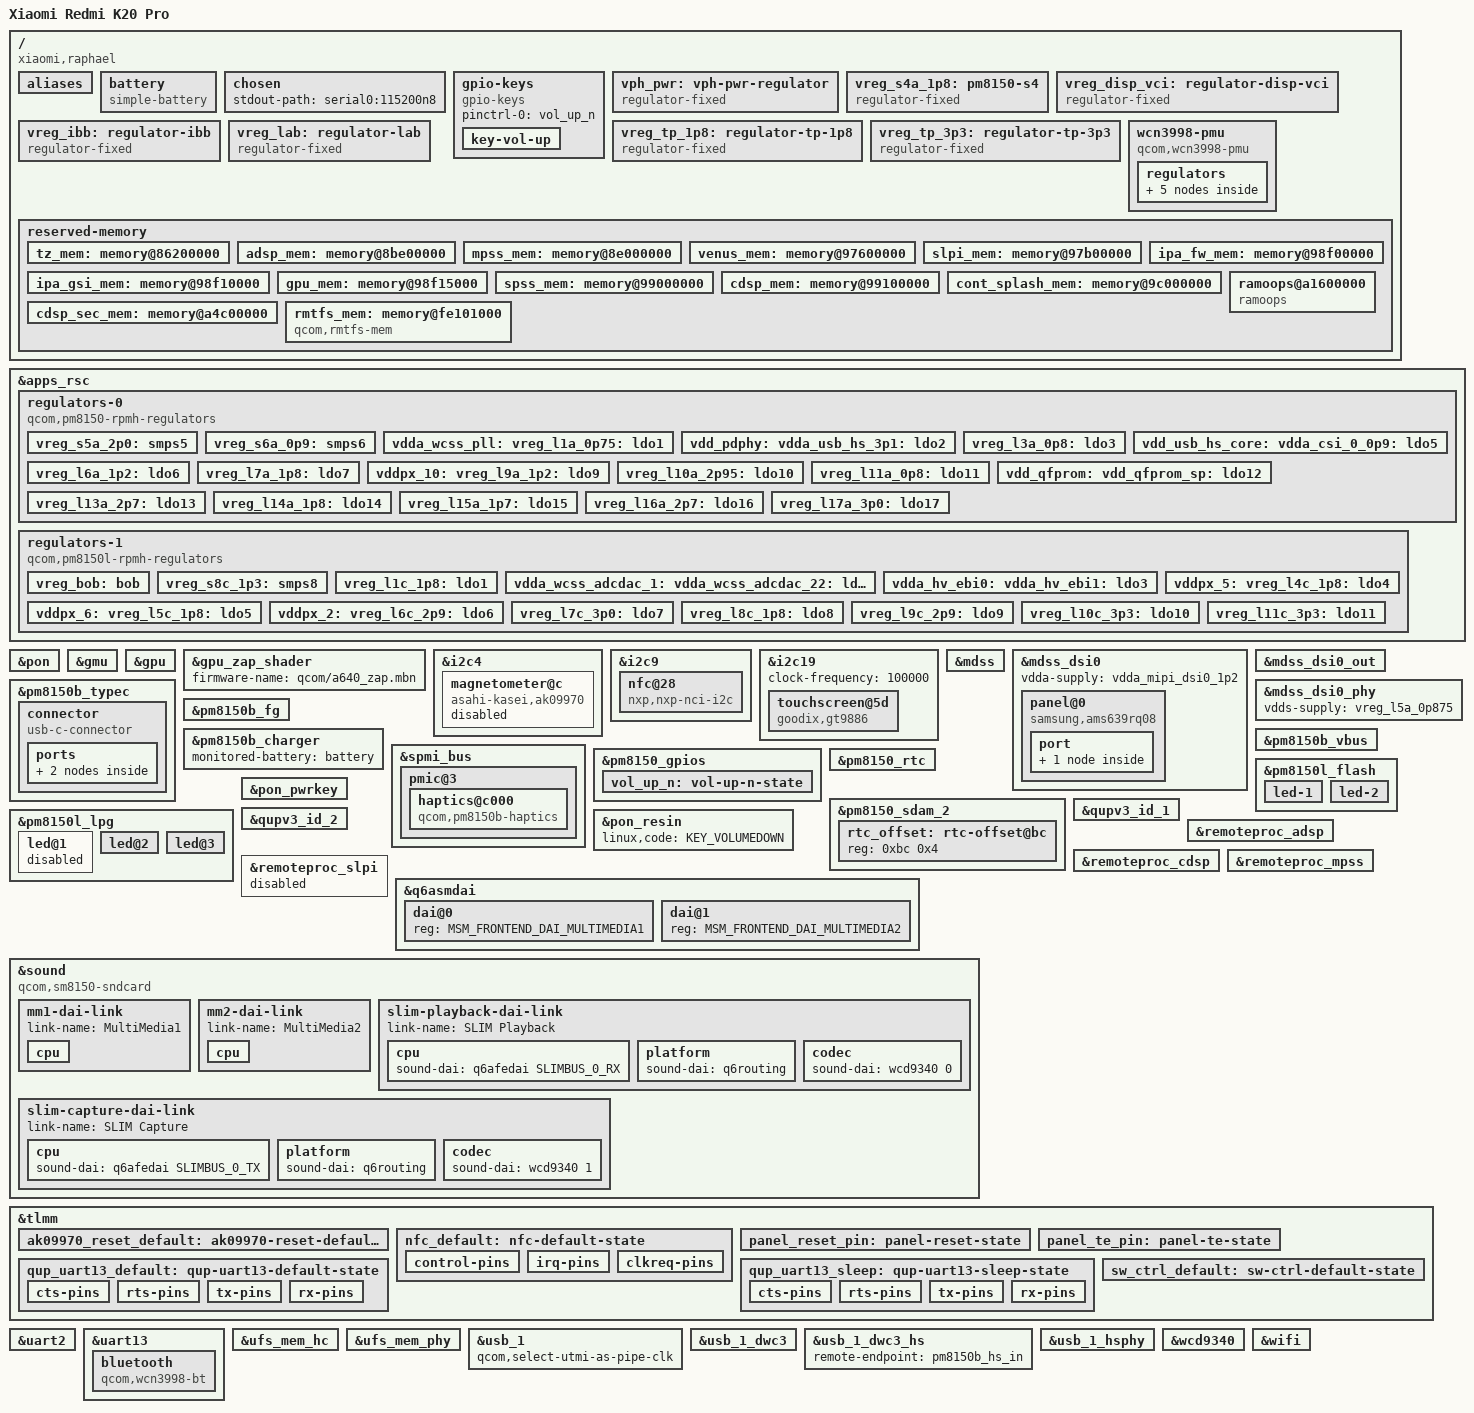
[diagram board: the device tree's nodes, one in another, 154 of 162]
// SPDX-License-Identifier: BSD-3-Clause
/*
 * Copyright (c) 2017-2019, The Linux Foundation. All rights reserved.
 * Copyright (c) 2019, Linaro Limited
 * Copyright (c) 2025, Piyush Raj Chouhan <piyushchouhan1598@gmail.com>
 */

/dts-v1/;

#include <dt-bindings/gpio/gpio.h>
#include <dt-bindings/interrupt-controller/irq.h>
#include <dt-bindings/leds/common.h>
#include <dt-bindings/pinctrl/qcom,pmic-gpio.h>
#include <dt-bindings/regulator/qcom,rpmh-regulator.h>
#include <dt-bindings/sound/qcom,q6afe.h>
#include <dt-bindings/sound/qcom,q6asm.h>
#include <dt-bindings/usb/pd.h>
#include "sm8150.dtsi"
#include "pm8150.dtsi"
#include "pm8150b.dtsi"
#include "pm8150l.dtsi"
#include "sm8150-wcd9340.dtsi"

/* Raphael firmware uses a board-specific reserved-memory layout. */
/delete-node/ &tz_mem;
/delete-node/ &rmtfs_mem;
/delete-node/ &adsp_mem;
/delete-node/ &mpss_mem;
/delete-node/ &venus_mem;
/delete-node/ &slpi_mem;
/delete-node/ &ipa_fw_mem;
/delete-node/ &ipa_gsi_mem;
/delete-node/ &gpu_mem;
/delete-node/ &spss_mem;
/delete-node/ &cdsp_mem;

/ {
	model = "Xiaomi Redmi K20 Pro";
	compatible = "xiaomi,raphael", "qcom,sm8150";
	qcom,msm-id = <339 0x20000>; /* SM8150 v2 */
	qcom,board-id = <40 0>;
	chassis-type = "handset";

	aliases {
		bluetooth0 = &bluetooth;
		serial0 = &uart2;
		serial1 = &uart13;
		wifi0 = &wifi;
	};

	battery: battery {
		compatible = "simple-battery";
		device-chemistry = "lithium-ion-polymer";

		/* Keep rapid-validation charging below the product driver's 1.95 A. */
		constant-charge-current-max-microamp = <1500000>;
		charge-full-design-microamp-hours = <4000000>;
		voltage-min-design-microvolt = <3400000>;
		voltage-max-design-microvolt = <4400000>;
	};

	chosen {
		stdout-path = "serial0:115200n8";
	};

	gpio-keys {
		compatible = "gpio-keys";

		pinctrl-0 = <&vol_up_n>;
		pinctrl-names = "default";

		key-vol-up {
			label = "Volume Up";
			linux,code = <KEY_VOLUMEUP>;
			gpios = <&pm8150_gpios 6 GPIO_ACTIVE_LOW>;
		};
	};

	vph_pwr: vph-pwr-regulator {
		compatible = "regulator-fixed";
		regulator-name = "vph_pwr";
		regulator-min-microvolt = <3700000>;
		regulator-max-microvolt = <3700000>;
	};

	/* PM8150 S4 is always on but is not exposed through RPMh. */
	vreg_s4a_1p8: pm8150-s4 {
		compatible = "regulator-fixed";
		regulator-name = "vreg_s4a_1p8";
		regulator-min-microvolt = <1800000>;
		regulator-max-microvolt = <1800000>;
		regulator-always-on;
		regulator-boot-on;
		vin-supply = <&vph_pwr>;
	};

	vreg_disp_vci: regulator-disp-vci {
		compatible = "regulator-fixed";
		regulator-name = "vreg_disp_vci";
		gpio = <&tlmm 99 GPIO_ACTIVE_HIGH>;
		enable-active-high;
		regulator-boot-on;
	};

	/* These rails are left enabled by the firmware display handoff. */
	vreg_ibb: regulator-ibb {
		compatible = "regulator-fixed";
		regulator-name = "ibb";
		regulator-min-microvolt = <6000000>;
		regulator-max-microvolt = <6000000>;
	};

	vreg_lab: regulator-lab {
		compatible = "regulator-fixed";
		regulator-name = "lab";
		regulator-min-microvolt = <6000000>;
		regulator-max-microvolt = <6000000>;
	};

	vreg_tp_1p8: regulator-tp-1p8 {
		compatible = "regulator-fixed";
		regulator-name = "vreg_tp_1p8";
		regulator-min-microvolt = <1800000>;
		regulator-max-microvolt = <1800000>;
		gpio = <&tlmm 100 GPIO_ACTIVE_HIGH>;
		enable-active-high;
		regulator-boot-on;
		startup-delay-us = <5000>;
	};

	vreg_tp_3p3: regulator-tp-3p3 {
		compatible = "regulator-fixed";
		regulator-name = "vreg_tp_3p3";
		regulator-min-microvolt = <3300000>;
		regulator-max-microvolt = <3300000>;
		gpio = <&tlmm 98 GPIO_ACTIVE_HIGH>;
		enable-active-high;
		regulator-boot-on;
		startup-delay-us = <5000>;
	};

	wcn3998-pmu {
		compatible = "qcom,wcn3998-pmu";

		pinctrl-0 = <&sw_ctrl_default>;
		pinctrl-names = "default";

		vddio-supply = <&vreg_s4a_1p8>;
		vddxo-supply = <&vreg_l7a_1p8>;
		vddrf-supply = <&vreg_l2c_1p3>;
		vddch0-supply = <&vreg_l11c_3p3>;
		vddch1-supply = <&vreg_l10c_3p3>;

		swctrl-gpios = <&tlmm 50 GPIO_ACTIVE_HIGH>;

		regulators {
			vreg_pmu_io: ldo0 {
				regulator-name = "vreg_pmu_io";
			};

			vreg_pmu_xo: ldo1 {
				regulator-name = "vreg_pmu_xo";
			};

			vreg_pmu_rf: ldo2 {
				regulator-name = "vreg_pmu_rf";
			};

			vreg_pmu_ch0: ldo3 {
				regulator-name = "vreg_pmu_ch0";
			};

			vreg_pmu_ch1: ldo4 {
				regulator-name = "vreg_pmu_ch1";
			};
		};
	};

	reserved-memory {
		tz_mem: memory@86200000 {
			reg = <0x0 0x86200000 0x0 0x5500000>;
			no-map;
		};

		adsp_mem: memory@8be00000 {
			reg = <0x0 0x8be00000 0x0 0x2200000>;
			no-map;
		};

		mpss_mem: memory@8e000000 {
			reg = <0x0 0x8e000000 0x0 0x9600000>;
			no-map;
		};

		venus_mem: memory@97600000 {
			reg = <0x0 0x97600000 0x0 0x500000>;
			no-map;
		};

		slpi_mem: memory@97b00000 {
			reg = <0x0 0x97b00000 0x0 0x1400000>;
			no-map;
		};

		ipa_fw_mem: memory@98f00000 {
			reg = <0x0 0x98f00000 0x0 0x10000>;
			no-map;
		};

		ipa_gsi_mem: memory@98f10000 {
			reg = <0x0 0x98f10000 0x0 0x5000>;
			no-map;
		};

		gpu_mem: memory@98f15000 {
			reg = <0x0 0x98f15000 0x0 0x2000>;
			no-map;
		};

		spss_mem: memory@99000000 {
			reg = <0x0 0x99000000 0x0 0x100000>;
			no-map;
		};

		cdsp_mem: memory@99100000 {
			reg = <0x0 0x99100000 0x0 0x1400000>;
			no-map;
		};

		cont_splash_mem: memory@9c000000 {
			reg = <0x0 0x9c000000 0x0 0x2400000>;
			no-map;
		};

		cdsp_sec_mem: memory@a4c00000 {
			reg = <0x0 0xa4c00000 0x0 0x3c00000>;
			no-map;
		};

		ramoops@a1600000 {
			compatible = "ramoops";
			reg = <0x0 0xa1600000 0x0 0x800000>;
			console-size = <0x400000>;
			ecc-size = <0>;
			ftrace-size = <0x20000>;
			pmsg-size = <0x200000>;
			record-size = <0x20000>;
			no-map;
		};

		rmtfs_mem: memory@fe101000 {
			compatible = "qcom,rmtfs-mem";
			reg = <0x0 0xfe101000 0x0 0x300000>;
			no-map;
			qcom,client-id = <1>;
			qcom,vmid = <15>;
		};
	};
};

&apps_rsc {
	regulators-0 {
		compatible = "qcom,pm8150-rpmh-regulators";
		qcom,pmic-id = "a";

		vdd-s1-supply = <&vph_pwr>;
		vdd-s2-supply = <&vph_pwr>;
		vdd-s3-supply = <&vph_pwr>;
		vdd-s4-supply = <&vph_pwr>;
		vdd-s5-supply = <&vph_pwr>;
		vdd-s6-supply = <&vph_pwr>;
		vdd-s7-supply = <&vph_pwr>;
		vdd-s8-supply = <&vph_pwr>;
		vdd-s9-supply = <&vph_pwr>;
		vdd-s10-supply = <&vph_pwr>;

		vdd-l1-l8-l11-supply = <&vreg_s6a_0p9>;
		vdd-l2-l10-supply = <&vreg_bob>;
		vdd-l3-l4-l5-l18-supply = <&vreg_s6a_0p9>;
		vdd-l6-l9-supply = <&vreg_s8c_1p3>;
		vdd-l7-l12-l14-l15-supply = <&vreg_s5a_2p0>;
		vdd-l13-l16-l17-supply = <&vreg_bob>;

		vreg_s5a_2p0: smps5 {
			regulator-min-microvolt = <1904000>;
			regulator-max-microvolt = <2000000>;
		};

		vreg_s6a_0p9: smps6 {
			regulator-min-microvolt = <920000>;
			regulator-max-microvolt = <1128000>;
		};

		vdda_wcss_pll:
		vreg_l1a_0p75: ldo1 {
			regulator-min-microvolt = <752000>;
			regulator-max-microvolt = <752000>;
			regulator-initial-mode = <RPMH_REGULATOR_MODE_HPM>;
		};

		vdd_pdphy:
		vdda_usb_hs_3p1:
		vreg_l2a_3p1: ldo2 {
			regulator-min-microvolt = <3072000>;
			regulator-max-microvolt = <3072000>;
			regulator-initial-mode = <RPMH_REGULATOR_MODE_HPM>;
		};

		vreg_l3a_0p8: ldo3 {
			regulator-min-microvolt = <480000>;
			regulator-max-microvolt = <932000>;
			regulator-initial-mode = <RPMH_REGULATOR_MODE_HPM>;
		};

		vdd_usb_hs_core:
		vdda_csi_0_0p9:
		vdda_csi_1_0p9:
		vdda_csi_2_0p9:
		vdda_csi_3_0p9:
		vdda_dsi_0_0p9:
		vdda_dsi_1_0p9:
		vdda_dsi_0_pll_0p9:
		vdda_dsi_1_pll_0p9:
		vdda_pcie_1ln_core:
		vdda_pcie_2ln_core:
		vdda_pll_hv_cc_ebi01:
		vdda_pll_hv_cc_ebi23:
		vdda_qrefs_0p875_5:
		vdda_sp_sensor:
		vdda_ufs_2ln_core_1:
		vdda_ufs_2ln_core_2:
		vdda_usb_ss_dp_core_1:
		vdda_usb_ss_dp_core_2:
		vdda_qlink_lv:
		vdda_qlink_lv_ck:
		vreg_l5a_0p875: ldo5 {
			regulator-min-microvolt = <880000>;
			regulator-max-microvolt = <880000>;
			regulator-initial-mode = <RPMH_REGULATOR_MODE_HPM>;
		};

		vreg_l6a_1p2: ldo6 {
			regulator-min-microvolt = <1200000>;
			regulator-max-microvolt = <1200000>;
			regulator-initial-mode = <RPMH_REGULATOR_MODE_HPM>;
		};

		vreg_l7a_1p8: ldo7 {
			regulator-min-microvolt = <1800000>;
			regulator-max-microvolt = <1800000>;
			regulator-initial-mode = <RPMH_REGULATOR_MODE_HPM>;
		};

		vddpx_10:
		vreg_l9a_1p2: ldo9 {
			regulator-min-microvolt = <1200000>;
			regulator-max-microvolt = <1200000>;
			regulator-initial-mode = <RPMH_REGULATOR_MODE_HPM>;
		};

		vreg_l10a_2p95: ldo10 {
			regulator-min-microvolt = <2950000>;
			regulator-max-microvolt = <2960000>;
			regulator-initial-mode = <RPMH_REGULATOR_MODE_HPM>;
		};

		vreg_l11a_0p8: ldo11 {
			regulator-min-microvolt = <800000>;
			regulator-max-microvolt = <800000>;
			regulator-initial-mode = <RPMH_REGULATOR_MODE_HPM>;
		};

		vdd_qfprom:
		vdd_qfprom_sp:
		vdda_apc_cs_1p8:
		vdda_gfx_cs_1p8:
		vdda_usb_hs_1p8:
		vdda_qrefs_vref_1p8:
		vddpx_10_a:
		vreg_l12a_1p8: ldo12 {
			regulator-min-microvolt = <1800000>;
			regulator-max-microvolt = <1800000>;
			regulator-initial-mode = <RPMH_REGULATOR_MODE_HPM>;
		};

		vreg_l13a_2p7: ldo13 {
			regulator-min-microvolt = <2704000>;
			regulator-max-microvolt = <2704000>;
			regulator-initial-mode = <RPMH_REGULATOR_MODE_HPM>;
		};

		vreg_l14a_1p8: ldo14 {
			regulator-min-microvolt = <1800000>;
			regulator-max-microvolt = <1880000>;
			regulator-initial-mode = <RPMH_REGULATOR_MODE_HPM>;
		};

		vreg_l15a_1p7: ldo15 {
			regulator-min-microvolt = <1704000>;
			regulator-max-microvolt = <1704000>;
			regulator-initial-mode = <RPMH_REGULATOR_MODE_HPM>;
		};

		vreg_l16a_2p7: ldo16 {
			regulator-min-microvolt = <2704000>;
			regulator-max-microvolt = <2960000>;
			regulator-initial-mode = <RPMH_REGULATOR_MODE_HPM>;
		};

		vreg_l17a_3p0: ldo17 {
			regulator-min-microvolt = <2856000>;
			regulator-max-microvolt = <3008000>;
			regulator-initial-mode = <RPMH_REGULATOR_MODE_HPM>;
		};
	};

	regulators-1 {
		compatible = "qcom,pm8150l-rpmh-regulators";
		qcom,pmic-id = "c";

		vdd-s1-supply = <&vph_pwr>;
		vdd-s2-supply = <&vph_pwr>;
		vdd-s3-supply = <&vph_pwr>;
		vdd-s4-supply = <&vph_pwr>;
		vdd-s5-supply = <&vph_pwr>;
		vdd-s6-supply = <&vph_pwr>;
		vdd-s7-supply = <&vph_pwr>;
		vdd-s8-supply = <&vph_pwr>;

		vdd-l1-l8-supply = <&vreg_s4a_1p8>;
		vdd-l2-l3-supply = <&vreg_s8c_1p3>;
		vdd-l4-l5-l6-supply = <&vreg_bob>;
		vdd-l7-l11-supply = <&vreg_bob>;
		vdd-l9-l10-supply = <&vreg_bob>;
		vdd-bob-supply = <&vph_pwr>;
		vdd-flash-supply = <&vreg_bob>;
		vdd-rgb-supply = <&vreg_bob>;

		vreg_bob: bob {
			regulator-min-microvolt = <3008000>;
			regulator-max-microvolt = <4000000>;
			regulator-initial-mode = <RPMH_REGULATOR_MODE_AUTO>;
			regulator-allow-bypass;
		};

		vreg_s8c_1p3: smps8 {
			regulator-min-microvolt = <1352000>;
			regulator-max-microvolt = <1352000>;
		};

		vreg_l1c_1p8: ldo1 {
			regulator-min-microvolt = <1800000>;
			regulator-max-microvolt = <1800000>;
			regulator-initial-mode = <RPMH_REGULATOR_MODE_HPM>;
		};

		vdda_wcss_adcdac_1:
		vdda_wcss_adcdac_22:
		vreg_l2c_1p3: ldo2 {
			regulator-min-microvolt = <1304000>;
			regulator-max-microvolt = <1304000>;
			regulator-initial-mode = <RPMH_REGULATOR_MODE_HPM>;
		};

		vdda_hv_ebi0:
		vdda_hv_ebi1:
		vdda_hv_ebi2:
		vdda_hv_ebi3:
		vdda_hv_refgen0:
		vdda_mipi_dsi0_1p2:
		vdda_qlink_hv_ck:
		vreg_l3c_1p2: ldo3 {
			regulator-min-microvolt = <1200000>;
			regulator-max-microvolt = <1200000>;
			regulator-initial-mode = <RPMH_REGULATOR_MODE_HPM>;
		};

		vddpx_5:
		vreg_l4c_1p8: ldo4 {
			regulator-min-microvolt = <1704000>;
			regulator-max-microvolt = <2928000>;
			regulator-initial-mode = <RPMH_REGULATOR_MODE_HPM>;
		};

		vddpx_6:
		vreg_l5c_1p8: ldo5 {
			regulator-min-microvolt = <1704000>;
			regulator-max-microvolt = <2928000>;
			regulator-initial-mode = <RPMH_REGULATOR_MODE_HPM>;
		};

		vddpx_2:
		vreg_l6c_2p9: ldo6 {
			regulator-min-microvolt = <1800000>;
			regulator-max-microvolt = <2960000>;
			regulator-initial-mode = <RPMH_REGULATOR_MODE_HPM>;
		};

		vreg_l7c_3p0: ldo7 {
			regulator-min-microvolt = <2856000>;
			regulator-max-microvolt = <3104000>;
			regulator-initial-mode = <RPMH_REGULATOR_MODE_HPM>;
		};

		vreg_l8c_1p8: ldo8 {
			regulator-min-microvolt = <1800000>;
			regulator-max-microvolt = <1800000>;
			regulator-initial-mode = <RPMH_REGULATOR_MODE_HPM>;
		};

		vreg_l9c_2p9: ldo9 {
			regulator-min-microvolt = <2704000>;
			regulator-max-microvolt = <2960000>;
			regulator-initial-mode = <RPMH_REGULATOR_MODE_HPM>;
		};

		vreg_l10c_3p3: ldo10 {
			regulator-min-microvolt = <3000000>;
			regulator-max-microvolt = <3312000>;
			regulator-initial-mode = <RPMH_REGULATOR_MODE_HPM>;
		};

		vreg_l11c_3p3: ldo11 {
			regulator-min-microvolt = <3000000>;
			regulator-max-microvolt = <3312000>;
			regulator-initial-mode = <RPMH_REGULATOR_MODE_HPM>;
		};
	};
};

&pon {
	mode-bootloader = <0x2>;
	mode-recovery = <0x1>;
};

&gmu {
	status = "okay";
};

&gpu {
	status = "okay";
};

&gpu_zap_shader {
	firmware-name = "qcom/a640_zap.mbn";
};

/*
 * The stock DTBO puts the AK09970 on QUPv3 SE4 at address 0x0c.  Keep both
 * the controller and sensor disabled until an attended ID/read-only test;
 * this records the wiring without probing or powering the mechanism.
 */
&i2c4 {
	magnetometer@c {
		compatible = "asahi-kasei,ak09970";
		reg = <0x0c>;

		vdd-supply = <&vreg_l8c_1p8>;
		reset-gpios = <&tlmm 11 GPIO_ACTIVE_LOW>;

		pinctrl-0 = <&ak09970_reset_default>;
		pinctrl-names = "default";
		status = "disabled";
	};
};

/*
 * The stock Raphael DTBO selects QUP9 for its NQ-series NFC controller.
 * Keep the generic NXP NCI compatible until the controller identifies itself
 * on hardware; the stock image carries support for several NQ3xx variants.
 */
&i2c9 {
	status = "okay";

	nfc@28 {
		compatible = "nxp,nxp-nci-i2c";
		reg = <0x28>;

		interrupt-parent = <&tlmm>;
		interrupts = <47 IRQ_TYPE_EDGE_RISING>;

		enable-gpios = <&tlmm 103 GPIO_ACTIVE_HIGH>;
		firmware-gpios = <&tlmm 48 GPIO_ACTIVE_HIGH>;

		pinctrl-0 = <&nfc_default>;
		pinctrl-names = "default";
	};
};

&i2c19 {
	clock-frequency = <100000>;
	status = "okay";

	touchscreen@5d {
		compatible = "goodix,gt9886";
		reg = <0x5d>;

		avdd-supply = <&vreg_tp_3p3>;
		vddio-supply = <&vreg_tp_1p8>;
		interrupts-extended = <&tlmm 122 IRQ_TYPE_LEVEL_LOW>;
		reset-gpios = <&tlmm 54 GPIO_ACTIVE_LOW>;
		touchscreen-size-x = <1080>;
		touchscreen-size-y = <2340>;
	};
};

&mdss {
	status = "okay";
};

&mdss_dsi0 {
	vdda-supply = <&vdda_mipi_dsi0_1p2>;
	status = "okay";

	panel@0 {
		compatible = "samsung,ams639rq08";
		reg = <0>;

		vddio-supply = <&vreg_l14a_1p8>;
		vdd3p3-supply = <&vreg_disp_vci>;
		vsn-supply = <&vreg_ibb>;
		vsp-supply = <&vreg_lab>;

		reset-gpios = <&tlmm 6 GPIO_ACTIVE_LOW>;
		pinctrl-0 = <&panel_reset_pin>, <&panel_te_pin>;
		pinctrl-names = "default";

		port {
			panel_in: endpoint {
				remote-endpoint = <&mdss_dsi0_out>;
			};
		};
	};
};

&mdss_dsi0_out {
	data-lanes = <0 1 2 3>;
	remote-endpoint = <&panel_in>;
};

&mdss_dsi0_phy {
	vdds-supply = <&vreg_l5a_0p875>;
	status = "okay";
};

&pm8150b_typec {
	vdd-vbus-supply = <&pm8150b_vbus>;
	vdd-pdphy-supply = <&vdda_usb_hs_3p1>;
	status = "okay";

	connector {
		compatible = "usb-c-connector";
		power-role = "dual";
		data-role = "dual";
		self-powered;

		source-pdos = <PDO_FIXED(5000, 3000, PDO_FIXED_DUAL_ROLE |
			       PDO_FIXED_USB_COMM | PDO_FIXED_DATA_SWAP)>;
		sink-pdos = <PDO_FIXED(5000, 3000, PDO_FIXED_DUAL_ROLE |
			     PDO_FIXED_USB_COMM | PDO_FIXED_DATA_SWAP)>;
		op-sink-microwatt = <10000000>;

		ports {
			#address-cells = <1>;
			#size-cells = <0>;

			port@0 {
				reg = <0>;

				pm8150b_hs_in: endpoint {
					remote-endpoint = <&usb_1_dwc3_hs>;
				};
			};
		};
	};
};

&pm8150b_fg {
	monitored-battery = <&battery>;
	power-supplies = <&pm8150b_charger>;
	status = "okay";
};

&pm8150b_charger {
	monitored-battery = <&battery>;
	status = "okay";
};

&pm8150b_vbus {
	regulator-min-microamp = <500000>;
	regulator-max-microamp = <1500000>;
	status = "okay";
};

&spmi_bus {
	pmic@3 {
		haptics@c000 {
			compatible = "qcom,pm8150b-haptics";
			reg = <0xc000>;
			interrupts = <0x3 0xc0 0 IRQ_TYPE_EDGE_BOTH>,
				     <0x3 0xc0 1 IRQ_TYPE_EDGE_BOTH>;
			interrupt-names = "hap-sc-irq", "hap-play-irq";

			/* Stock Raphael uses a 3 V ERM at a 6667 us sample rate. */
			qcom,actuator-type = "erm";
			qcom,vmax-mv = <3000>;
			qcom,play-rate-us = <6667>;
		};
	};
};

&pm8150_gpios {
	vol_up_n: vol-up-n-state {
		pins = "gpio6";
		function = PMIC_GPIO_FUNC_NORMAL;
		input-enable;
		bias-pull-up;
	};
};

&pm8150_rtc {
	nvmem-cells = <&rtc_offset>;
	nvmem-cell-names = "offset";
	status = "okay";
};

&pm8150_sdam_2 {
	status = "okay";

	rtc_offset: rtc-offset@bc {
		reg = <0xbc 0x4>;
	};
};

&pm8150l_flash {
	status = "okay";

	led-1 {
		function = LED_FUNCTION_FLASH;
		color = <LED_COLOR_ID_WHITE>;
		led-sources = <1>;
		led-max-microamp = <150000>;
		flash-max-microamp = <1000000>;
		flash-max-timeout-us = <1280000>;
	};

	led-2 {
		function = LED_FUNCTION_FLASH;
		color = <LED_COLOR_ID_YELLOW>;
		led-sources = <2>;
		led-max-microamp = <150000>;
		flash-max-microamp = <1000000>;
		flash-max-timeout-us = <1280000>;
	};
};

&pm8150l_lpg {
	status = "okay";

	led@1 {
		reg = <1>;
		color = <LED_COLOR_ID_WHITE>;
		function = LED_FUNCTION_STATUS;
		status = "disabled";
	};

	led@2 {
		reg = <2>;
		color = <LED_COLOR_ID_RED>;
		function = LED_FUNCTION_STATUS;
		function-enumerator = <0>;
	};

	led@3 {
		reg = <3>;
		color = <LED_COLOR_ID_RED>;
		function = LED_FUNCTION_STATUS;
		function-enumerator = <1>;
	};
};

&pon_pwrkey {
	status = "okay";
};

&pon_resin {
	linux,code = <KEY_VOLUMEDOWN>;
	status = "okay";
};

&qupv3_id_1 {
	status = "okay";
};

&qupv3_id_2 {
	status = "okay";
};

&remoteproc_adsp {
	firmware-name = "qcom/sm8150/Xiaomi/raphael/adsp.mdt";
	status = "okay";
};

&remoteproc_cdsp {
	firmware-name = "qcom/sm8150/Xiaomi/raphael/cdsp.mdt";
	status = "okay";
};

&remoteproc_mpss {
	firmware-name = "qcom/sm8150/Xiaomi/raphael/modem.mdt";
	status = "okay";
};

/* SLPI repeatedly crashes with the available firmware; keep it quarantined. */
&remoteproc_slpi {
	status = "disabled";
};

&q6asmdai {
	dai@0 {
		reg = <MSM_FRONTEND_DAI_MULTIMEDIA1>;
	};

	dai@1 {
		reg = <MSM_FRONTEND_DAI_MULTIMEDIA2>;
	};
};

&sound {
	compatible = "qcom,sm8150-sndcard", "qcom,sdm845-sndcard";
	model = "Xiaomi-Raphael-WCD9340";

	audio-routing =
		"RX_BIAS", "MCLK",
		"AMIC1", "MIC BIAS3",
		"AMIC2", "MIC BIAS2",
		"AMIC3", "MIC BIAS4";

	mm1-dai-link {
		link-name = "MultiMedia1";

		cpu {
			sound-dai = <&q6asmdai MSM_FRONTEND_DAI_MULTIMEDIA1>;
		};
	};

	mm2-dai-link {
		link-name = "MultiMedia2";

		cpu {
			sound-dai = <&q6asmdai MSM_FRONTEND_DAI_MULTIMEDIA2>;
		};
	};

	slim-playback-dai-link {
		link-name = "SLIM Playback";

		cpu {
			sound-dai = <&q6afedai SLIMBUS_0_RX>;
		};

		platform {
			sound-dai = <&q6routing>;
		};

		codec {
			sound-dai = <&wcd9340 0>;
		};
	};

	slim-capture-dai-link {
		link-name = "SLIM Capture";

		cpu {
			sound-dai = <&q6afedai SLIMBUS_0_TX>;
		};

		platform {
			sound-dai = <&q6routing>;
		};

		codec {
			sound-dai = <&wcd9340 1>;
		};
	};
};

&tlmm {
	ak09970_reset_default: ak09970-reset-default-state {
		pins = "gpio11";
		function = "gpio";
		drive-strength = <2>;
		bias-disable;
		output-low;
	};

	nfc_default: nfc-default-state {
		control-pins {
			pins = "gpio48", "gpio103";
			function = "gpio";
			drive-strength = <2>;
			bias-disable;
		};

		irq-pins {
			pins = "gpio47";
			function = "gpio";
			drive-strength = <2>;
			bias-pull-up;
		};

		/* CLKREQ is observed by the downstream driver but not consumed. */
		clkreq-pins {
			pins = "gpio113";
			function = "gpio";
			drive-strength = <2>;
			bias-pull-up;
		};
	};

	panel_reset_pin: panel-reset-state {
		pins = "gpio6";
		function = "gpio";
		drive-strength = <2>;
		bias-disable;
		output-low;
	};

	panel_te_pin: panel-te-state {
		pins = "gpio8";
		function = "mdp_vsync";
		drive-strength = <2>;
		bias-pull-down;
	};

	qup_uart13_default: qup-uart13-default-state {
		cts-pins {
			pins = "gpio43";
			function = "qup13";
			drive-strength = <2>;
			bias-bus-hold;
		};

		rts-pins {
			pins = "gpio44";
			function = "qup13";
			drive-strength = <2>;
			bias-disable;
		};

		tx-pins {
			pins = "gpio45";
			function = "qup13";
			drive-strength = <2>;
			bias-disable;
		};

		rx-pins {
			pins = "gpio46";
			function = "qup13";
			drive-strength = <2>;
			bias-pull-up;
		};
	};

	qup_uart13_sleep: qup-uart13-sleep-state {
		cts-pins {
			pins = "gpio43";
			function = "gpio";
			drive-strength = <2>;
			bias-bus-hold;
		};

		rts-pins {
			pins = "gpio44";
			function = "gpio";
			drive-strength = <2>;
			bias-pull-down;
		};

		tx-pins {
			pins = "gpio45";
			function = "gpio";
			drive-strength = <2>;
			bias-pull-up;
		};

		rx-pins {
			pins = "gpio46";
			function = "gpio";
			drive-strength = <2>;
			bias-pull-up;
		};
	};

	sw_ctrl_default: sw-ctrl-default-state {
		pins = "gpio50";
		function = "gpio";
		bias-pull-down;
	};
};

&uart2 {
	status = "okay";
};

&uart13 {
	/delete-property/ interrupts;
	interrupts-extended = <&intc GIC_SPI 585 IRQ_TYPE_LEVEL_HIGH>,
			      <&tlmm 46 IRQ_TYPE_EDGE_FALLING>;
	pinctrl-0 = <&qup_uart13_default>;
	pinctrl-1 = <&qup_uart13_sleep>;
	pinctrl-names = "default", "sleep";
	status = "okay";

	bluetooth: bluetooth {
		compatible = "qcom,wcn3998-bt";

		vddio-supply = <&vreg_pmu_io>;
		vddxo-supply = <&vreg_pmu_xo>;
		vddrf-supply = <&vreg_pmu_rf>;
		vddch0-supply = <&vreg_pmu_ch0>;
	};
};

&ufs_mem_hc {
	reset-gpios = <&tlmm 175 GPIO_ACTIVE_LOW>;

	vcc-supply = <&vreg_l10a_2p95>;
	vcc-max-microamp = <750000>;
	vccq-supply = <&vreg_l9a_1p2>;
	vccq-max-microamp = <700000>;
	vccq2-supply = <&vreg_s4a_1p8>;
	vccq2-max-microamp = <750000>;

	status = "okay";
};

&ufs_mem_phy {
	vdda-phy-supply = <&vdda_ufs_2ln_core_1>;
	vdda-pll-supply = <&vreg_l3c_1p2>;

	status = "okay";
};

&usb_1 {
	qcom,select-utmi-as-pipe-clk;
	status = "okay";
};

&usb_1_dwc3 {
	dr_mode = "peripheral";
	maximum-speed = "high-speed";
	phys = <&usb_1_hsphy>;
	phy-names = "usb2-phy";
};

&usb_1_dwc3_hs {
	remote-endpoint = <&pm8150b_hs_in>;
};

&usb_1_hsphy {
	vdda-pll-supply = <&vdd_usb_hs_core>;
	vdda33-supply = <&vdda_usb_hs_3p1>;
	vdda18-supply = <&vdda_usb_hs_1p8>;
	status = "okay";
};

&wcd9340 {
	reset-gpios = <&tlmm 143 GPIO_ACTIVE_HIGH>;
	vdd-buck-sido-supply = <&vreg_s4a_1p8>;
	vdd-buck-supply = <&vreg_s4a_1p8>;
	vdd-tx-supply = <&vreg_s4a_1p8>;
	vdd-rx-supply = <&vreg_s4a_1p8>;
	vdd-io-supply = <&vreg_s4a_1p8>;

	qcom,micbias1-microvolt = <1800000>;
	qcom,micbias2-microvolt = <2750000>;
	qcom,micbias3-microvolt = <1800000>;
	qcom,micbias4-microvolt = <1800000>;

	qcom,mbhc-buttons-vthreshold-microvolt =
		<75000 150000 237000 500000 500000 500000 500000 500000>;
	qcom,mbhc-headset-vthreshold-microvolt = <2600000>;
	qcom,mbhc-headphone-vthreshold-microvolt = <50000>;
};

&wifi {
	vdd-0.8-cx-mx-supply = <&vdda_wcss_pll>;
	vdd-1.8-xo-supply = <&vreg_pmu_xo>;
	vdd-1.3-rfa-supply = <&vreg_pmu_rf>;
	vdd-3.3-ch0-supply = <&vreg_pmu_ch0>;
	vdd-3.3-ch1-supply = <&vreg_pmu_ch1>;

	qcom,calibration-variant = "Xiaomi_raphael";
	status = "okay";
};
